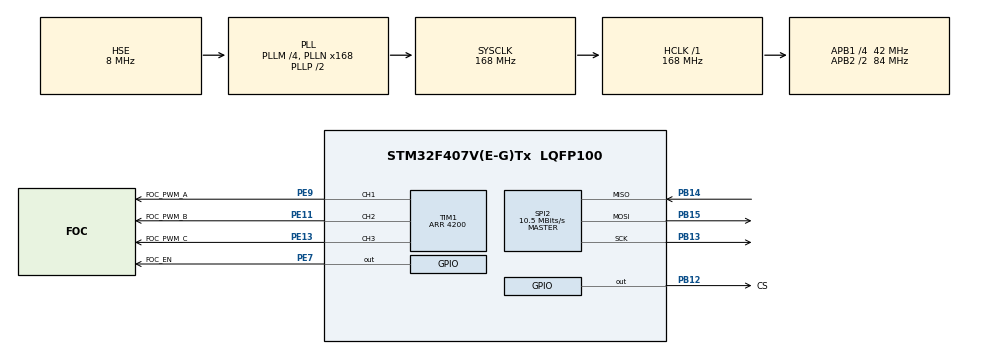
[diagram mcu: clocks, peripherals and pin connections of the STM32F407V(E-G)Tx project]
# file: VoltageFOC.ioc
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Mcu.Family=STM32F4
Mcu.Name=STM32F407V(E-G)Tx
Mcu.Package=LQFP100
NVIC.PriorityGroup=NVIC_PRIORITYGROUP_0
PA13.Mode=Serial_Wire
PA13.Signal=SYS_JTMS-SWDIO
PA14.Mode=Serial_Wire
PA14.Signal=SYS_JTCK-SWCLK
PB12.GPIO_Label=CS
PB12.PinState=GPIO_PIN_SET
PB12.Signal=GPIO_Output
PB13.Mode=Full_Duplex_Master
PB13.Signal=SPI2_SCK
PB14.Mode=Full_Duplex_Master
PB14.Signal=SPI2_MISO
PB15.Mode=Full_Duplex_Master
PB15.Signal=SPI2_MOSI
PE11.GPIO_Label=FOC_PWM_B
PE11.GPIO_Speed=GPIO_SPEED_FREQ_VERY_HIGH
PE11.Signal=S_TIM1_CH2
PE13.GPIO_Label=FOC_PWM_C
PE13.GPIO_Speed=GPIO_SPEED_FREQ_VERY_HIGH
PE13.Signal=S_TIM1_CH3
PE7.GPIO_Label=FOC_EN
PE7.Signal=GPIO_Output
PE9.GPIO_Label=FOC_PWM_A
PE9.GPIO_Speed=GPIO_SPEED_FREQ_VERY_HIGH
PE9.Signal=S_TIM1_CH1
PH0-OSC_IN.Mode=HSE-External-Oscillator
PH0-OSC_IN.Signal=RCC_OSC_IN
PH1-OSC_OUT.Mode=HSE-External-Oscillator
PH1-OSC_OUT.Signal=RCC_OSC_OUT
ProjectManager.HeapSize=0x200
ProjectManager.StackSize=0x400
ProjectManager.TargetToolchain=STM32CubeIDE
RCC.48MHZClocksFreq_Value=48000000
RCC.AHBFreq_Value=168000000
RCC.APB1CLKDivider=RCC_HCLK_DIV4
RCC.APB1Freq_Value=42000000
RCC.APB1TimFreq_Value=84000000
RCC.APB2CLKDivider=RCC_HCLK_DIV2
RCC.APB2Freq_Value=84000000
RCC.APB2TimFreq_Value=168000000
RCC.CortexFreq_Value=168000000
RCC.HCLKFreq_Value=168000000
RCC.HSE_VALUE=8000000
RCC.HSI_VALUE=16000000
RCC.LSE_VALUE=32768
RCC.PLLM=4
RCC.PLLN=168
RCC.PLLQ=7
RCC.PLLSourceVirtual=RCC_PLLSOURCE_HSE
RCC.SYSCLKFreq_VALUE=168000000
RCC.SYSCLKSource=RCC_SYSCLKSOURCE_PLLCLK
RCC.VCOOutputFreq_Value=336000000
SH.S_TIM1_CH1.0=TIM1_CH1,PWM Generation1 CH1
SH.S_TIM1_CH2.0=TIM1_CH2,PWM Generation2 CH2
SH.S_TIM1_CH3.0=TIM1_CH3,PWM Generation3 CH3
SPI2.BaudRatePrescaler=SPI_BAUDRATEPRESCALER_4
SPI2.CLKPhase=SPI_PHASE_1EDGE
SPI2.CLKPolarity=SPI_POLARITY_HIGH
SPI2.CalculateBaudRate=10.5 MBits/s
SPI2.Direction=SPI_DIRECTION_2LINES
SPI2.Mode=SPI_MODE_MASTER
SPI2.VirtualType=VM_MASTER
TIM1.AutoReloadPreload=TIM_AUTORELOAD_PRELOAD_ENABLE
TIM1.Channel-PWM\ Generation1\ CH1=TIM_CHANNEL_1
TIM1.Channel-PWM\ Generation2\ CH2=TIM_CHANNEL_2
TIM1.Channel-PWM\ Generation3\ CH3=TIM_CHANNEL_3
TIM1.CounterMode=TIM_COUNTERMODE_CENTERALIGNED1
TIM1.Period=4200
TIM1.RepetitionCounter=1
VP_TIM1_VS_ClockSourceINT.Mode=Internal
board=STM32F407G-DISC1

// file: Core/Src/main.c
/* USER CODE BEGIN Header */
/**
  ******************************************************************************
  * @file           : main.c
  * @brief          : Main program body
  ******************************************************************************
  * @attention
  *
  * Copyright (c) 2026 STMicroelectronics.
  * All rights reserved.
  *
  * This software is licensed under terms that can be found in the LICENSE file
  * in the root directory of this software component.
  * If no LICENSE file comes with this software, it is provided AS-IS.
  *
  ******************************************************************************
  */
/* USER CODE END Header */
#include "main.h"

/* USER CODE BEGIN Includes */
//#include "mt6701.h"
#include "foc_app.h"   /* FOC: enkoder + PWM + kontrol */

/* USER CODE END Includes */

SPI_HandleTypeDef hspi2;

TIM_HandleTypeDef htim1;

void SystemClock_Config(void);
static void MX_GPIO_Init(void);
static void MX_SPI2_Init(void);
static void MX_TIM1_Init(void);

int main(void)
{

  /* MCU Configuration--------------------------------------------------------*/

  /* Reset of all peripherals, Initializes the Flash interface and the Systick. */
  HAL_Init();

  /* Configure the system clock */
  SystemClock_Config();

  /* Initialize all configured peripherals */
  MX_GPIO_Init();
  MX_SPI2_Init();
  MX_TIM1_Init();
  /* USER CODE BEGIN 2 */
  //MT6701_Init(&encoder, GPIOB, GPIO_PIN_12, GPIOB, GPIO_PIN_13, GPIOB, GPIO_PIN_14);
  /* Eski polling sürücüsü FOC ile aynı SPI2'yi kullandığı için kapatıldı:
  MT6701_Init(&encoder, &hspi2, CS_GPIO_Port, CS_Pin); */
  FocApp_Init();   /* enkoder -> kutup çifti tespiti -> hizalama -> 20 kHz FOC kesmesi.
                      Durum: g_app_state (Live Expressions ile izle) */
  /* USER CODE END 2 */

  /* Infinite loop */
  while (1)
  {

    /* USER CODE BEGIN 3 */
	  /* Komutlar (g_cmd) ve Ke ölçümü; FOC'un kendisi TIM1 kesmesinde çalışır.
	     Eski MT6701_ReadData döngüsü kaldırıldı (yedek: main.c.bak). */
	  FocApp_Loop();
	  HAL_Delay(1);
  }
  /* USER CODE END 3 */
}

void SystemClock_Config(void)
{
  RCC_OscInitTypeDef RCC_OscInitStruct = {0};
  RCC_ClkInitTypeDef RCC_ClkInitStruct = {0};

  /** Configure the main internal regulator output voltage
  */
  __HAL_RCC_PWR_CLK_ENABLE();
  __HAL_PWR_VOLTAGESCALING_CONFIG(PWR_REGULATOR_VOLTAGE_SCALE1);

  /** Initializes the RCC Oscillators according to the specified parameters
  * in the RCC_OscInitTypeDef structure.
  */
  RCC_OscInitStruct.OscillatorType = RCC_OSCILLATORTYPE_HSE;
  RCC_OscInitStruct.HSEState = RCC_HSE_ON;
  RCC_OscInitStruct.PLL.PLLState = RCC_PLL_ON;
  RCC_OscInitStruct.PLL.PLLSource = RCC_PLLSOURCE_HSE;
  RCC_OscInitStruct.PLL.PLLM = 4;
  RCC_OscInitStruct.PLL.PLLN = 168;
  RCC_OscInitStruct.PLL.PLLP = RCC_PLLP_DIV2;
  RCC_OscInitStruct.PLL.PLLQ = 7;
  if (HAL_RCC_OscConfig(&RCC_OscInitStruct) != HAL_OK)
  {
    Error_Handler();
  }

  /** Initializes the CPU, AHB and APB buses clocks
  */
  RCC_ClkInitStruct.ClockType = RCC_CLOCKTYPE_HCLK|RCC_CLOCKTYPE_SYSCLK
                              |RCC_CLOCKTYPE_PCLK1|RCC_CLOCKTYPE_PCLK2;
  RCC_ClkInitStruct.SYSCLKSource = RCC_SYSCLKSOURCE_PLLCLK;
  RCC_ClkInitStruct.AHBCLKDivider = RCC_SYSCLK_DIV1;
  RCC_ClkInitStruct.APB1CLKDivider = RCC_HCLK_DIV4;
  RCC_ClkInitStruct.APB2CLKDivider = RCC_HCLK_DIV2;

  if (HAL_RCC_ClockConfig(&RCC_ClkInitStruct, FLASH_LATENCY_5) != HAL_OK)
  {
    Error_Handler();
  }
}

static void MX_SPI2_Init(void)
{

  /* SPI2 parameter configuration*/
  hspi2.Instance = SPI2;
  hspi2.Init.Mode = SPI_MODE_MASTER;
  hspi2.Init.Direction = SPI_DIRECTION_2LINES;
  hspi2.Init.DataSize = SPI_DATASIZE_8BIT;
  hspi2.Init.CLKPolarity = SPI_POLARITY_HIGH;
  hspi2.Init.CLKPhase = SPI_PHASE_1EDGE;
  hspi2.Init.NSS = SPI_NSS_SOFT;
  hspi2.Init.BaudRatePrescaler = SPI_BAUDRATEPRESCALER_4;
  hspi2.Init.FirstBit = SPI_FIRSTBIT_MSB;
  hspi2.Init.TIMode = SPI_TIMODE_DISABLE;
  hspi2.Init.CRCCalculation = SPI_CRCCALCULATION_DISABLE;
  hspi2.Init.CRCPolynomial = 10;
  if (HAL_SPI_Init(&hspi2) != HAL_OK)
  {
    Error_Handler();
  }

}

static void MX_TIM1_Init(void)
{

  TIM_ClockConfigTypeDef sClockSourceConfig = {0};
  TIM_MasterConfigTypeDef sMasterConfig = {0};
  TIM_OC_InitTypeDef sConfigOC = {0};
  TIM_BreakDeadTimeConfigTypeDef sBreakDeadTimeConfig = {0};

  htim1.Instance = TIM1;
  htim1.Init.Prescaler = 0;
  htim1.Init.CounterMode = TIM_COUNTERMODE_CENTERALIGNED1;
  htim1.Init.Period = 4200;
  htim1.Init.ClockDivision = TIM_CLOCKDIVISION_DIV1;
  htim1.Init.RepetitionCounter = 1;
  htim1.Init.AutoReloadPreload = TIM_AUTORELOAD_PRELOAD_ENABLE;
  if (HAL_TIM_Base_Init(&htim1) != HAL_OK)
  {
    Error_Handler();
  }
  sClockSourceConfig.ClockSource = TIM_CLOCKSOURCE_INTERNAL;
  if (HAL_TIM_ConfigClockSource(&htim1, &sClockSourceConfig) != HAL_OK)
  {
    Error_Handler();
  }
  if (HAL_TIM_PWM_Init(&htim1) != HAL_OK)
  {
    Error_Handler();
  }
  sMasterConfig.MasterOutputTrigger = TIM_TRGO_RESET;
  sMasterConfig.MasterSlaveMode = TIM_MASTERSLAVEMODE_DISABLE;
  if (HAL_TIMEx_MasterConfigSynchronization(&htim1, &sMasterConfig) != HAL_OK)
  {
    Error_Handler();
  }
  sConfigOC.OCMode = TIM_OCMODE_PWM1;
  sConfigOC.Pulse = 0;
  sConfigOC.OCPolarity = TIM_OCPOLARITY_HIGH;
  sConfigOC.OCNPolarity = TIM_OCNPOLARITY_HIGH;
  sConfigOC.OCFastMode = TIM_OCFAST_DISABLE;
  sConfigOC.OCIdleState = TIM_OCIDLESTATE_RESET;
  sConfigOC.OCNIdleState = TIM_OCNIDLESTATE_RESET;
  if (HAL_TIM_PWM_ConfigChannel(&htim1, &sConfigOC, TIM_CHANNEL_1) != HAL_OK)
  {
    Error_Handler();
  }
  if (HAL_TIM_PWM_ConfigChannel(&htim1, &sConfigOC, TIM_CHANNEL_2) != HAL_OK)
  {
    Error_Handler();
  }
  if (HAL_TIM_PWM_ConfigChannel(&htim1, &sConfigOC, TIM_CHANNEL_3) != HAL_OK)
  {
    Error_Handler();
  }
  sBreakDeadTimeConfig.OffStateRunMode = TIM_OSSR_DISABLE;
  sBreakDeadTimeConfig.OffStateIDLEMode = TIM_OSSI_DISABLE;
  sBreakDeadTimeConfig.LockLevel = TIM_LOCKLEVEL_OFF;
  sBreakDeadTimeConfig.DeadTime = 0;
  sBreakDeadTimeConfig.BreakState = TIM_BREAK_DISABLE;
  sBreakDeadTimeConfig.BreakPolarity = TIM_BREAKPOLARITY_HIGH;
  sBreakDeadTimeConfig.AutomaticOutput = TIM_AUTOMATICOUTPUT_DISABLE;
  if (HAL_TIMEx_ConfigBreakDeadTime(&htim1, &sBreakDeadTimeConfig) != HAL_OK)
  {
    Error_Handler();
  }
  HAL_TIM_MspPostInit(&htim1);

}

static void MX_GPIO_Init(void)
{
  GPIO_InitTypeDef GPIO_InitStruct = {0};

  /* GPIO Ports Clock Enable */
  __HAL_RCC_GPIOH_CLK_ENABLE();
  __HAL_RCC_GPIOE_CLK_ENABLE();
  __HAL_RCC_GPIOB_CLK_ENABLE();
  __HAL_RCC_GPIOA_CLK_ENABLE();

  /*Configure GPIO pin Output Level */
  HAL_GPIO_WritePin(FOC_EN_GPIO_Port, FOC_EN_Pin, GPIO_PIN_RESET);

  /*Configure GPIO pin Output Level */
  HAL_GPIO_WritePin(CS_GPIO_Port, CS_Pin, GPIO_PIN_SET);

  /*Configure GPIO pin : FOC_EN_Pin */
  GPIO_InitStruct.Pin = FOC_EN_Pin;
  GPIO_InitStruct.Mode = GPIO_MODE_OUTPUT_PP;
  GPIO_InitStruct.Pull = GPIO_NOPULL;
  GPIO_InitStruct.Speed = GPIO_SPEED_FREQ_LOW;
  HAL_GPIO_Init(FOC_EN_GPIO_Port, &GPIO_InitStruct);

  /*Configure GPIO pin : CS_Pin */
  GPIO_InitStruct.Pin = CS_Pin;
  GPIO_InitStruct.Mode = GPIO_MODE_OUTPUT_PP;
  GPIO_InitStruct.Pull = GPIO_NOPULL;
  GPIO_InitStruct.Speed = GPIO_SPEED_FREQ_LOW;
  HAL_GPIO_Init(CS_GPIO_Port, &GPIO_InitStruct);

}

void Error_Handler(void)
{
  __disable_irq();
  while (1)
  {
  }
}
